VERSION ""

NS_ :

BS_:

BU_: XXX

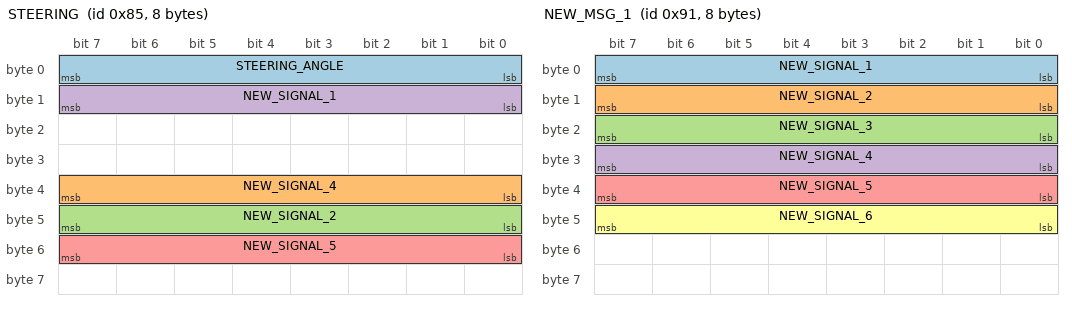
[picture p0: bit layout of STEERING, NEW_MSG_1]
BO_ 133 STEERING: 8 XXX
 SG_ STEERING_ANGLE : 7|8@0+ (1,0) [0|255] "" XXX
 SG_ NEW_SIGNAL_4 : 39|8@0+ (1,0) [0|255] "" XXX
 SG_ NEW_SIGNAL_2 : 47|8@0+ (1,0) [0|255] "" XXX
 SG_ NEW_SIGNAL_1 : 15|8@0+ (1,0) [0|255] "" XXX
 SG_ NEW_SIGNAL_5 : 55|8@0+ (1,0) [0|255] "" XXX

BO_ 145 NEW_MSG_1: 8 XXX
 SG_ NEW_SIGNAL_1 : 0|8@1+ (1,0) [0|255] "" XXX
 SG_ NEW_SIGNAL_2 : 15|8@0+ (1,0) [0|255] "" XXX
 SG_ NEW_SIGNAL_3 : 23|8@0+ (1,0) [0|255] "" XXX
 SG_ NEW_SIGNAL_4 : 31|8@0+ (1,0) [0|255] "" XXX
 SG_ NEW_SIGNAL_5 : 39|8@0+ (1,0) [0|255] "" XXX
 SG_ NEW_SIGNAL_6 : 47|8@0+ (1,0) [0|255] "" XXX

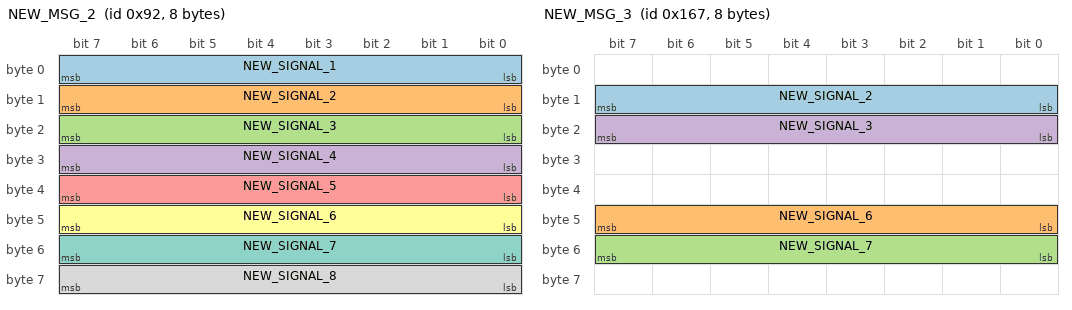
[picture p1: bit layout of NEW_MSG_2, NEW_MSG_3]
BO_ 146 NEW_MSG_2: 8 XXX
 SG_ NEW_SIGNAL_1 : 7|8@0+ (1,0) [0|255] "" XXX
 SG_ NEW_SIGNAL_2 : 15|8@0+ (1,0) [0|255] "" XXX
 SG_ NEW_SIGNAL_3 : 23|8@0+ (1,0) [0|255] "" XXX
 SG_ NEW_SIGNAL_4 : 31|8@0+ (1,0) [0|255] "" XXX
 SG_ NEW_SIGNAL_5 : 39|8@0+ (1,0) [0|255] "" XXX
 SG_ NEW_SIGNAL_6 : 47|8@0+ (1,0) [0|255] "" XXX
 SG_ NEW_SIGNAL_7 : 55|8@0+ (1,0) [0|255] "" XXX
 SG_ NEW_SIGNAL_8 : 63|8@0+ (1,0) [0|255] "" XXX

BO_ 359 NEW_MSG_3: 8 XXX
 SG_ NEW_SIGNAL_2 : 15|8@0+ (1,0) [0|255] "" XXX
 SG_ NEW_SIGNAL_6 : 47|8@0+ (1,0) [0|255] "" XXX
 SG_ NEW_SIGNAL_7 : 55|8@0+ (1,0) [0|255] "" XXX
 SG_ NEW_SIGNAL_3 : 23|8@0+ (1,0) [0|255] "" XXX

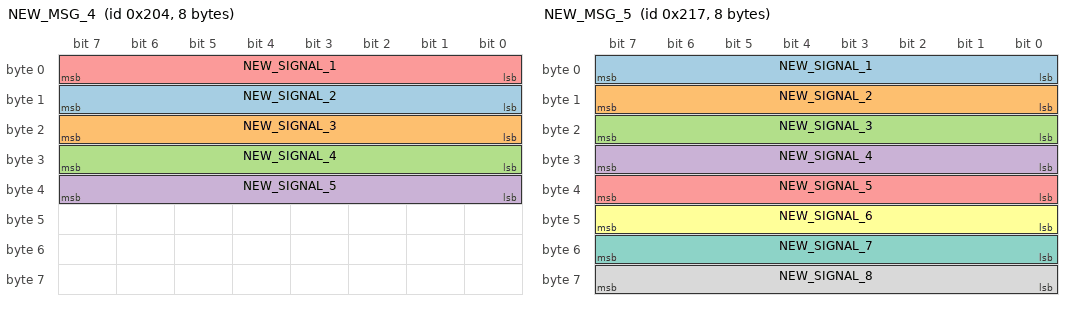
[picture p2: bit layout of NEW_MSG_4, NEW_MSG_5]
BO_ 516 NEW_MSG_4: 8 XXX
 SG_ NEW_SIGNAL_2 : 15|8@0+ (1,0) [0|255] "" XXX
 SG_ NEW_SIGNAL_3 : 23|8@0+ (1,0) [0|255] "" XXX
 SG_ NEW_SIGNAL_4 : 31|8@0+ (1,0) [0|255] "" XXX
 SG_ NEW_SIGNAL_5 : 39|8@0+ (1,0) [0|255] "" XXX
 SG_ NEW_SIGNAL_1 : 7|8@0+ (1,0) [0|255] "" XXX

BO_ 535 NEW_MSG_5: 8 XXX
 SG_ NEW_SIGNAL_1 : 7|8@0+ (1,0) [0|255] "" XXX
 SG_ NEW_SIGNAL_2 : 15|8@0+ (1,0) [0|255] "" XXX
 SG_ NEW_SIGNAL_3 : 23|8@0+ (1,0) [0|255] "" XXX
 SG_ NEW_SIGNAL_4 : 31|8@0+ (1,0) [0|255] "" XXX
 SG_ NEW_SIGNAL_5 : 39|8@0+ (1,0) [0|255] "" XXX
 SG_ NEW_SIGNAL_6 : 47|8@0+ (1,0) [0|255] "" XXX
 SG_ NEW_SIGNAL_7 : 55|8@0+ (1,0) [0|255] "" XXX
 SG_ NEW_SIGNAL_8 : 63|8@0+ (1,0) [0|255] "" XXX

BO_ 118 NEW_MSG_6: 8 XXX
 SG_ NEW_SIGNAL_1 : 7|8@0+ (1,0) [0|255] "" XXX
 SG_ NEW_SIGNAL_2 : 15|8@0+ (1,0) [0|255] "" XXX

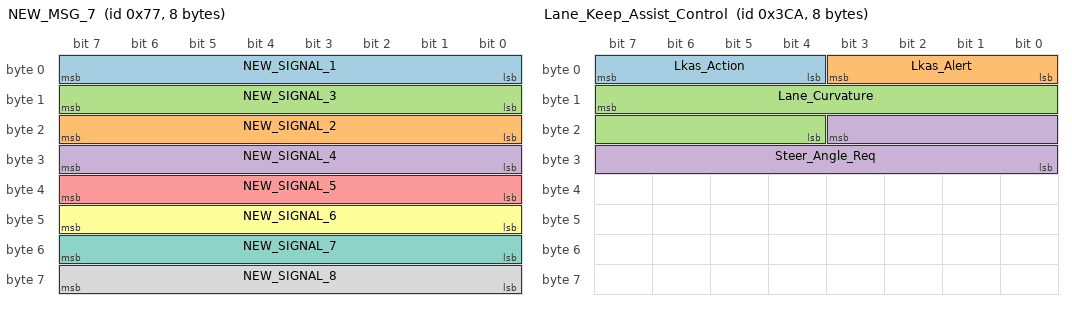
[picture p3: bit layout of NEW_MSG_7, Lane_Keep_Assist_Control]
BO_ 119 NEW_MSG_7: 8 XXX
 SG_ NEW_SIGNAL_1 : 7|8@0+ (1,0) [0|255] "" XXX
 SG_ NEW_SIGNAL_2 : 23|8@0+ (1,0) [0|255] "" XXX
 SG_ NEW_SIGNAL_3 : 15|8@0+ (1,0) [0|255] "" XXX
 SG_ NEW_SIGNAL_4 : 31|8@0+ (1,0) [0|255] "" XXX
 SG_ NEW_SIGNAL_5 : 39|8@0+ (1,0) [0|255] "" XXX
 SG_ NEW_SIGNAL_6 : 47|8@0+ (1,0) [0|255] "" XXX
 SG_ NEW_SIGNAL_7 : 55|8@0+ (1,0) [0|255] "" XXX
 SG_ NEW_SIGNAL_8 : 63|8@0+ (1,0) [0|255] "" XXX

BO_ 970 Lane_Keep_Assist_Control: 8 XXX
 SG_ Lkas_Action : 7|4@0+ (1,0) [0|15] "" XXX
 SG_ Lkas_Alert : 3|4@0+ (1,0) [0|15] "" XXX
 SG_ Lane_Curvature : 15|12@0+ (0.000005,-0.01) [0|0] "1/m" XXX
 SG_ Steer_Angle_Req : 19|12@0+ (0.04297,-88.00445) [0|0] "deg" XXX

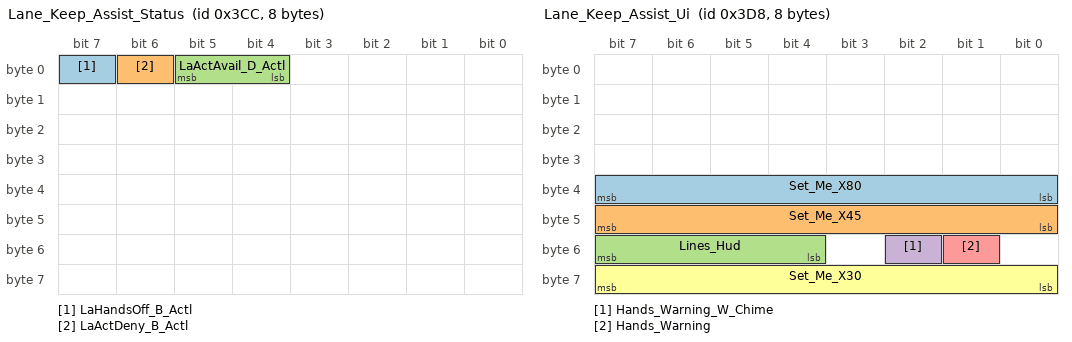
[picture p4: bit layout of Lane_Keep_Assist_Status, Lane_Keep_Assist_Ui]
BO_ 972 Lane_Keep_Assist_Status: 8 XXX
 SG_ LaHandsOff_B_Actl : 7|1@0+ (1,0) [0|0] "" XXX
 SG_ LaActDeny_B_Actl : 6|1@0+ (1,0) [0|0] "" XXX
 SG_ LaActAvail_D_Actl : 5|2@0+ (1,0) [0|0] "" XXX

BO_ 984 Lane_Keep_Assist_Ui: 8 XXX
 SG_ Set_Me_X80 : 39|8@0+ (1,0) [0|255] "" XXX
 SG_ Set_Me_X45 : 47|8@0+ (1,0) [0|255] "" XXX
 SG_ Lines_Hud : 55|4@0+ (1,0) [0|15] "" XXX
 SG_ Hands_Warning_W_Chime : 50|1@0+ (1,0) [0|1] "" XXX
 SG_ Hands_Warning : 49|1@0+ (1,0) [0|1] "" XXX
 SG_ Set_Me_X30 : 63|8@0+ (1,0) [0|255] "" XXX
